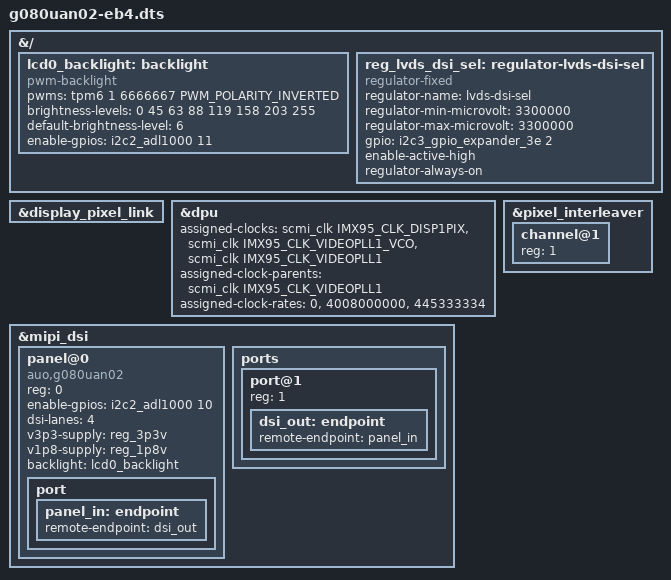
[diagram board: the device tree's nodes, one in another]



&{/} {

	lcd0_backlight: backlight {
		compatible = "pwm-backlight";
		pwms = <&tpm6 1 6666667 PWM_POLARITY_INVERTED>;
		brightness-levels = <0 45 63 88 119 158 203 255>;
		default-brightness-level = <6>;
		enable-gpios = <&i2c2_adl1000 11 GPIO_ACTIVE_HIGH>;	//DSI_BL_EN_1V8
	};

	//LVDS_DSI_SEL , 0:DSI , 1:LVDS
	reg_lvds_dsi_sel: regulator-lvds-dsi-sel {
		compatible = "regulator-fixed";
		regulator-name = "lvds-dsi-sel";
		regulator-min-microvolt = <3300000>;
		regulator-max-microvolt = <3300000>;
		gpio = <&i2c3_gpio_expander_3e 2 GPIO_ACTIVE_HIGH>;
		enable-active-high;
		regulator-always-on;
	};
};


&display_pixel_link {
	status = "okay";
};

&dpu {
	assigned-clocks = <&scmi_clk IMX95_CLK_DISP1PIX>,
			  <&scmi_clk IMX95_CLK_VIDEOPLL1_VCO>,
			  <&scmi_clk IMX95_CLK_VIDEOPLL1>;
	assigned-clock-parents = <&scmi_clk IMX95_CLK_VIDEOPLL1>;
	assigned-clock-rates = <0>, <4008000000>, <445333334>;
};

&mipi_dsi {
	#address-cells = <1>;
	#size-cells = <0>;
	status = "okay";

	panel@0 {
		compatible = "auo,g080uan02";
		reg = <0>;
		enable-gpios = <&i2c2_adl1000 10 GPIO_ACTIVE_HIGH>; //DSI_VDD_EN_1V8

		dsi-lanes = <4>;
		//v3p3-supply = <&reg_mux_sel>;
		v3p3-supply = <&reg_3p3v>;
		v1p8-supply = <&reg_1p8v>;
		backlight = <&lcd0_backlight>;

		port {
			panel_in: endpoint {
				remote-endpoint = <&dsi_out>;
			};
		};
	};

	ports {
		#address-cells = <1>;
		#size-cells = <0>;

		port@1 {
			reg = <1>;

			dsi_out: endpoint {
				remote-endpoint = <&panel_in>;
			};
		};
	};
};

&pixel_interleaver {
	#address-cells = <1>;
	#size-cells = <0>;
	status = "okay";

	channel@1 {
		reg = <1>;
		status = "okay";
	};
};
